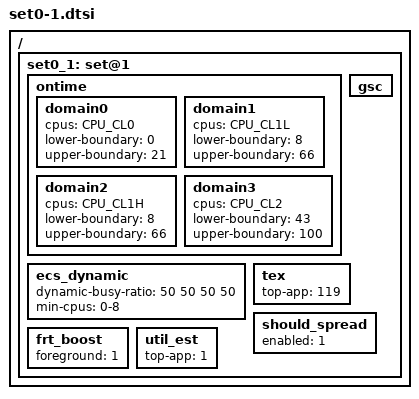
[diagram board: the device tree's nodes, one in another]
/ {
	/* normal mode - touch boost */
	set0_1: set@1 {
		/* Ontime Migration */
		ontime {
			domain0 {
				cpus = CPU_CL0;
				lower-boundary = <0>;
				upper-boundary = <21>;
			};
			domain1 {
				cpus = CPU_CL1L;
				lower-boundary = <8>;
				upper-boundary = <66>;
			};
			domain2 {
				cpus = CPU_CL1H;
				lower-boundary = <8>;
				upper-boundary = <66>;
			};
			domain3 {
				cpus = CPU_CL2;
				lower-boundary = <43>;
				upper-boundary = <100>;
			};
		};

		ecs_dynamic {
			dynamic-busy-ratio = <50 50 50 50>;
			min-cpus = "0-8";
		};

		gsc { };

		tex {
			top-app = <119>;
		};

		should_spread {
			enabled = <1>;
		};

		frt_boost {
			foreground = <1>;
		};

		util_est {
			top-app	= <1>;
		};
	};
};
